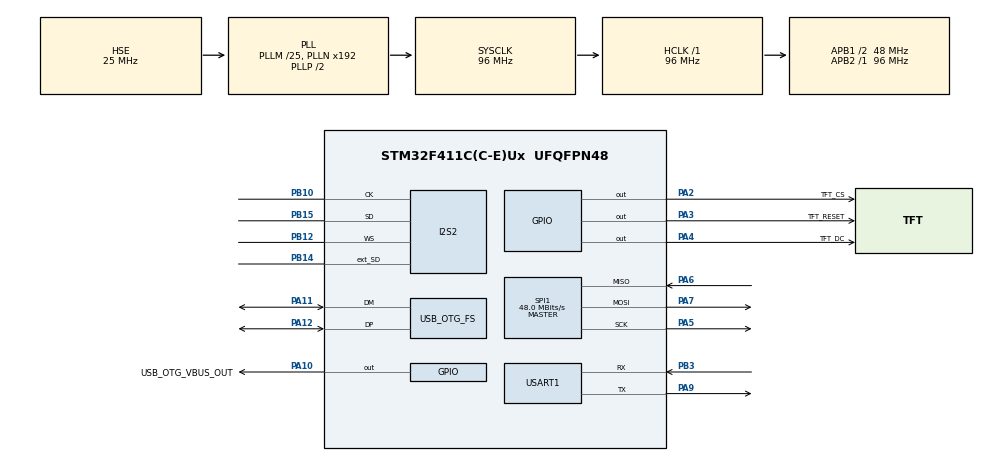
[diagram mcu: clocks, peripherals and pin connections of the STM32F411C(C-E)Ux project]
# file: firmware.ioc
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Dma.I2S2_EXT_TX.4.Direction=DMA_MEMORY_TO_PERIPH
Dma.I2S2_EXT_TX.4.FIFOMode=DMA_FIFOMODE_DISABLE
Dma.I2S2_EXT_TX.4.Instance=DMA1_Stream4
Dma.I2S2_EXT_TX.4.MemDataAlignment=DMA_MDATAALIGN_HALFWORD
Dma.I2S2_EXT_TX.4.MemInc=DMA_MINC_ENABLE
Dma.I2S2_EXT_TX.4.Mode=DMA_CIRCULAR
Dma.I2S2_EXT_TX.4.PeriphDataAlignment=DMA_PDATAALIGN_HALFWORD
Dma.I2S2_EXT_TX.4.PeriphInc=DMA_PINC_DISABLE
Dma.I2S2_EXT_TX.4.Priority=DMA_PRIORITY_VERY_HIGH
Dma.Request0=SPI1_TX
Dma.Request1=USART1_TX
Dma.Request2=USART1_RX
Dma.Request3=SPI2_RX
Dma.Request4=I2S2_EXT_TX
Dma.SPI1_TX.0.Direction=DMA_MEMORY_TO_PERIPH
Dma.SPI1_TX.0.FIFOMode=DMA_FIFOMODE_DISABLE
Dma.SPI1_TX.0.Instance=DMA2_Stream2
Dma.SPI1_TX.0.MemDataAlignment=DMA_MDATAALIGN_BYTE
Dma.SPI1_TX.0.MemInc=DMA_MINC_ENABLE
Dma.SPI1_TX.0.Mode=DMA_NORMAL
Dma.SPI1_TX.0.PeriphDataAlignment=DMA_PDATAALIGN_BYTE
Dma.SPI1_TX.0.PeriphInc=DMA_PINC_DISABLE
Dma.SPI1_TX.0.Priority=DMA_PRIORITY_LOW
Dma.SPI2_RX.3.Direction=DMA_PERIPH_TO_MEMORY
Dma.SPI2_RX.3.FIFOMode=DMA_FIFOMODE_DISABLE
Dma.SPI2_RX.3.Instance=DMA1_Stream3
Dma.SPI2_RX.3.MemDataAlignment=DMA_MDATAALIGN_HALFWORD
Dma.SPI2_RX.3.MemInc=DMA_MINC_ENABLE
Dma.SPI2_RX.3.Mode=DMA_CIRCULAR
Dma.SPI2_RX.3.PeriphDataAlignment=DMA_PDATAALIGN_HALFWORD
Dma.SPI2_RX.3.PeriphInc=DMA_PINC_DISABLE
Dma.SPI2_RX.3.Priority=DMA_PRIORITY_VERY_HIGH
Dma.USART1_RX.2.Direction=DMA_PERIPH_TO_MEMORY
Dma.USART1_RX.2.FIFOMode=DMA_FIFOMODE_DISABLE
Dma.USART1_RX.2.Instance=DMA2_Stream5
Dma.USART1_RX.2.MemDataAlignment=DMA_MDATAALIGN_BYTE
Dma.USART1_RX.2.MemInc=DMA_MINC_ENABLE
Dma.USART1_RX.2.Mode=DMA_NORMAL
Dma.USART1_RX.2.PeriphDataAlignment=DMA_PDATAALIGN_BYTE
Dma.USART1_RX.2.PeriphInc=DMA_PINC_DISABLE
Dma.USART1_RX.2.Priority=DMA_PRIORITY_LOW
Dma.USART1_TX.1.Direction=DMA_MEMORY_TO_PERIPH
Dma.USART1_TX.1.FIFOMode=DMA_FIFOMODE_DISABLE
Dma.USART1_TX.1.Instance=DMA2_Stream7
Dma.USART1_TX.1.MemDataAlignment=DMA_MDATAALIGN_BYTE
Dma.USART1_TX.1.MemInc=DMA_MINC_ENABLE
Dma.USART1_TX.1.Mode=DMA_NORMAL
Dma.USART1_TX.1.PeriphDataAlignment=DMA_PDATAALIGN_BYTE
Dma.USART1_TX.1.PeriphInc=DMA_PINC_DISABLE
Dma.USART1_TX.1.Priority=DMA_PRIORITY_LOW
FREERTOS.Tasks01=defaultTask,24,128,StartDefaultTask,Default,NULL,Dynamic,NULL,NULL
I2S2.AudioFreq=AudioFreqCustomValue
I2S2.AudioFreqCustom=44100
I2S2.ErrorAudioFreq=0.23 %
I2S2.FullDuplexMode=I2S_FULLDUPLEXMODE_ENABLE
I2S2.Instance=SPI$Index
I2S2.Mode=I2S_MODE_MASTER_RX
I2S2.RealAudioFreq=44.102 KHz
I2S2.VirtualMode=I2S_MODE_MASTER
Mcu.Family=STM32F4
Mcu.Name=STM32F411C(C-E)Ux
Mcu.Package=UFQFPN48
NVIC.DMA1_Stream3_IRQn=true\:5\:0\:false\:false\:true\:true\:false\:true
NVIC.DMA1_Stream4_IRQn=true\:5\:0\:false\:false\:true\:true\:false\:true
NVIC.DMA2_Stream2_IRQn=true\:5\:0\:false\:false\:true\:true\:false\:true
NVIC.DMA2_Stream5_IRQn=true\:5\:0\:false\:false\:true\:true\:false\:true
NVIC.DMA2_Stream7_IRQn=true\:5\:0\:false\:false\:true\:true\:false\:true
NVIC.OTG_FS_IRQn=true\:5\:0\:false\:false\:true\:true\:true\:true
NVIC.PriorityGroup=NVIC_PRIORITYGROUP_4
NVIC.SPI1_IRQn=true\:5\:0\:false\:false\:true\:true\:true\:true
NVIC.SPI2_IRQn=true\:5\:0\:false\:false\:true\:true\:true\:true
NVIC.TIM5_IRQn=true\:15\:0\:false\:false\:true\:false\:false\:true
NVIC.TimeBase=TIM5_IRQn
NVIC.TimeBaseIP=TIM5
NVIC.USART1_IRQn=true\:5\:0\:false\:false\:true\:true\:true\:true
PA10.GPIO_Label=USB_OTG_VBUS_OUT
PA10.Signal=GPIO_Output
PA11.Mode=Host_Only
PA11.Signal=USB_OTG_FS_DM
PA12.Mode=Host_Only
PA12.Signal=USB_OTG_FS_DP
PA13.Mode=Serial_Wire
PA13.Signal=SYS_JTMS-SWDIO
PA14.Mode=Serial_Wire
PA14.Signal=SYS_JTCK-SWCLK
PA2.GPIO_Label=TFT_CS
PA2.GPIO_Speed=GPIO_SPEED_FREQ_HIGH
PA2.Signal=GPIO_Output
PA3.GPIO_Label=TFT_RESET
PA3.Signal=GPIO_Output
PA4.GPIO_Label=TFT_DC
PA4.GPIO_Speed=GPIO_SPEED_FREQ_HIGH
PA4.PinState=GPIO_PIN_RESET
PA4.Signal=GPIO_Output
PA5.Mode=Full_Duplex_Master
PA5.Signal=SPI1_SCK
PA6.Mode=Full_Duplex_Master
PA6.Signal=SPI1_MISO
PA7.Mode=Full_Duplex_Master
PA7.Signal=SPI1_MOSI
PA9.Mode=Asynchronous
PA9.Signal=USART1_TX
PB10.Mode=Full_Duplex_Master
PB10.Signal=I2S2_CK
PB12.Mode=Full_Duplex_Master
PB12.Signal=I2S2_WS
PB14.Mode=Full_Duplex_Master
PB14.Signal=I2S2_ext_SD
PB15.Mode=Full_Duplex_Master
PB15.Signal=I2S2_SD
PB3.Mode=Asynchronous
PB3.Signal=USART1_RX
PC14-OSC32_IN.Mode=LSE-External-Oscillator
PC14-OSC32_IN.Signal=RCC_OSC32_IN
PC15-OSC32_OUT.Mode=LSE-External-Oscillator
PC15-OSC32_OUT.Signal=RCC_OSC32_OUT
PH0\ -\ OSC_IN.Mode=HSE-External-Oscillator
PH0\ -\ OSC_IN.Signal=RCC_OSC_IN
PH1\ -\ OSC_OUT.Mode=HSE-External-Oscillator
PH1\ -\ OSC_OUT.Signal=RCC_OSC_OUT
ProjectManager.HeapSize=0x200
ProjectManager.StackSize=0x800
ProjectManager.TargetToolchain=Makefile
RCC.48MHZClocksFreq_Value=48000000
RCC.AHBFreq_Value=96000000
RCC.APB1CLKDivider=RCC_HCLK_DIV2
RCC.APB1Freq_Value=48000000
RCC.APB1TimFreq_Value=96000000
RCC.APB2Freq_Value=96000000
RCC.APB2TimFreq_Value=96000000
RCC.CortexFreq_Value=96000000
RCC.HCLKFreq_Value=96000000
RCC.HSE_VALUE=25000000
RCC.HSI_VALUE=16000000
RCC.PLLI2SM=12
RCC.PLLI2SN=63
RCC.PLLI2SR=3
RCC.PLLM=25
RCC.SYSCLKFreq_VALUE=96000000
RCC.SYSCLKSource=RCC_SYSCLKSOURCE_PLLCLK
RCC.VCOOutputFreq_Value=192000000
SPI1.BaudRatePrescaler=SPI_BAUDRATEPRESCALER_2
SPI1.CalculateBaudRate=48.0 MBits/s
SPI1.Direction=SPI_DIRECTION_2LINES
SPI1.Mode=SPI_MODE_MASTER
SPI1.VirtualType=VM_MASTER
USART1.VirtualMode=VM_ASYNC
USB_HOST.BSP.number=1
USB_HOST.USBH_DEBUG_LEVEL=3
USB_HOST.USBH_HandleTypeDef=hUsbHostFS
USB_HOST.USBH_PROCESS_STACK_SIZE=2*1024
USB_HOST.VirtualModeFS=All_Classes
USB_HOST0.BSP.STBoard=false
USB_HOST0.BSP.api=Unknown
USB_HOST0.BSP.i2caddr=0
USB_HOST0.BSP.instance=PA10
USB_HOST0.BSP.ip=GPIO
USB_HOST0.BSP.mode=Output
USB_HOST0.BSP.name=Drive_VBUS_FS
USB_HOST0.BSP.solution=PA10
USB_OTG_FS.VirtualMode=Host_Only
USB_OTG_FS.phy_itface=HCD_PHY_EMBEDDED
VP_FREERTOS_VS_CMSIS_V2.Mode=CMSIS_V2
VP_SYS_VS_tim5.Mode=TIM5
VP_USB_HOST_VS_USB_HOST_ALL_CLASS_FS.Mode=ALL_Classes_FS
board=custom

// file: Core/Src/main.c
/* USER CODE BEGIN Header */
/**
 ******************************************************************************
 * @file           : main.c
 * @brief          : Main program body
 ******************************************************************************
 * @attention
 *
 * <h2><center>&copy; Copyright (c) 2023 STMicroelectronics.
 * All rights reserved.</center></h2>
 *
 * This software component is licensed by ST under Ultimate Liberty license
 * SLA0044, the "License"; You may not use this file except in compliance with
 * the License. You may obtain a copy of the License at:
 *                             www.st.com/SLA0044
 *
 ******************************************************************************
 */
/* USER CODE END Header */
#include "main.h"
#include "cmsis_os.h"
#include "usb_host.h"
#include "usb_host.h"

/* USER CODE BEGIN Includes */
#include "platform.h"
#include "SEGGER_SYSVIEW.h"
/* USER CODE END Includes */

I2S_HandleTypeDef hi2s2;
DMA_HandleTypeDef hdma_spi2_rx;
DMA_HandleTypeDef hdma_i2s2_ext_tx;

SPI_HandleTypeDef hspi1;
DMA_HandleTypeDef hdma_spi1_tx;

UART_HandleTypeDef huart1;
DMA_HandleTypeDef hdma_usart1_tx;
DMA_HandleTypeDef hdma_usart1_rx;

/* Definitions for defaultTask */
osThreadId_t defaultTaskHandle;
const osThreadAttr_t defaultTask_attributes = {
  .name = "defaultTask",
  .stack_size = 128 * 4,
  .priority = (osPriority_t) osPriorityNormal,
};

void SystemClock_Config(void);
static void MX_GPIO_Init(void);
static void MX_DMA_Init(void);
static void MX_SPI1_Init(void);
static void MX_USART1_UART_Init(void);
static void MX_I2S2_Init(void);
void StartDefaultTask(void *argument);

/* USER CODE BEGIN 0 */
static volatile int uxTopUsedPriority;

/* USER CODE END 0 */

int main(void)
{
  /* USER CODE BEGIN 1 */
  uxTopUsedPriority = configMAX_PRIORITIES - 1;
  SEGGER_SYSVIEW_Conf();
  /* USER CODE END 1 */

  /* MCU Configuration--------------------------------------------------------*/

  /* Reset of all peripherals, Initializes the Flash interface and the Systick. */
  HAL_Init();

  /* Configure the system clock */
  SystemClock_Config();

  /* Initialize all configured peripherals */
  MX_GPIO_Init();
  MX_DMA_Init();
  MX_SPI1_Init();
  MX_USART1_UART_Init();
  MX_I2S2_Init();

  /* Init scheduler */
  osKernelInitialize();

  /* Create the thread(s) */
  /* creation of defaultTask */
  defaultTaskHandle = osThreadNew(StartDefaultTask, NULL, &defaultTask_attributes);

  /* Start scheduler */
  osKernelStart();

  /* We should never get here as control is now taken by the scheduler */
  /* Infinite loop */
    while (1) {

    }
}

void SystemClock_Config(void)
{
  RCC_OscInitTypeDef RCC_OscInitStruct = {0};
  RCC_ClkInitTypeDef RCC_ClkInitStruct = {0};

  /** Configure the main internal regulator output voltage
  */
  __HAL_RCC_PWR_CLK_ENABLE();
  __HAL_PWR_VOLTAGESCALING_CONFIG(PWR_REGULATOR_VOLTAGE_SCALE1);
  /** Initializes the RCC Oscillators according to the specified parameters
  * in the RCC_OscInitTypeDef structure.
  */
  RCC_OscInitStruct.OscillatorType = RCC_OSCILLATORTYPE_HSE;
  RCC_OscInitStruct.HSEState = RCC_HSE_ON;
  RCC_OscInitStruct.PLL.PLLState = RCC_PLL_ON;
  RCC_OscInitStruct.PLL.PLLSource = RCC_PLLSOURCE_HSE;
  RCC_OscInitStruct.PLL.PLLM = 25;
  RCC_OscInitStruct.PLL.PLLN = 192;
  RCC_OscInitStruct.PLL.PLLP = RCC_PLLP_DIV2;
  RCC_OscInitStruct.PLL.PLLQ = 4;
  if (HAL_RCC_OscConfig(&RCC_OscInitStruct) != HAL_OK)
  {
    Error_Handler();
  }
  /** Initializes the CPU, AHB and APB buses clocks
  */
  RCC_ClkInitStruct.ClockType = RCC_CLOCKTYPE_HCLK|RCC_CLOCKTYPE_SYSCLK
                              |RCC_CLOCKTYPE_PCLK1|RCC_CLOCKTYPE_PCLK2;
  RCC_ClkInitStruct.SYSCLKSource = RCC_SYSCLKSOURCE_PLLCLK;
  RCC_ClkInitStruct.AHBCLKDivider = RCC_SYSCLK_DIV1;
  RCC_ClkInitStruct.APB1CLKDivider = RCC_HCLK_DIV2;
  RCC_ClkInitStruct.APB2CLKDivider = RCC_HCLK_DIV1;

  if (HAL_RCC_ClockConfig(&RCC_ClkInitStruct, FLASH_LATENCY_3) != HAL_OK)
  {
    Error_Handler();
  }
}

static void MX_I2S2_Init(void)
{

  hi2s2.Instance = SPI2;
  hi2s2.Init.Mode = I2S_MODE_MASTER_RX;
  hi2s2.Init.Standard = I2S_STANDARD_PHILIPS;
  hi2s2.Init.DataFormat = I2S_DATAFORMAT_16B;
  hi2s2.Init.MCLKOutput = I2S_MCLKOUTPUT_DISABLE;
  hi2s2.Init.AudioFreq = 44100;
  hi2s2.Init.CPOL = I2S_CPOL_LOW;
  hi2s2.Init.ClockSource = I2S_CLOCK_PLL;
  hi2s2.Init.FullDuplexMode = I2S_FULLDUPLEXMODE_ENABLE;
  if (HAL_I2S_Init(&hi2s2) != HAL_OK)
  {
    Error_Handler();
  }

}

static void MX_SPI1_Init(void)
{

  /* SPI1 parameter configuration*/
  hspi1.Instance = SPI1;
  hspi1.Init.Mode = SPI_MODE_MASTER;
  hspi1.Init.Direction = SPI_DIRECTION_2LINES;
  hspi1.Init.DataSize = SPI_DATASIZE_8BIT;
  hspi1.Init.CLKPolarity = SPI_POLARITY_LOW;
  hspi1.Init.CLKPhase = SPI_PHASE_1EDGE;
  hspi1.Init.NSS = SPI_NSS_SOFT;
  hspi1.Init.BaudRatePrescaler = SPI_BAUDRATEPRESCALER_2;
  hspi1.Init.FirstBit = SPI_FIRSTBIT_MSB;
  hspi1.Init.TIMode = SPI_TIMODE_DISABLE;
  hspi1.Init.CRCCalculation = SPI_CRCCALCULATION_DISABLE;
  hspi1.Init.CRCPolynomial = 10;
  if (HAL_SPI_Init(&hspi1) != HAL_OK)
  {
    Error_Handler();
  }

}

static void MX_USART1_UART_Init(void)
{

  huart1.Instance = USART1;
  huart1.Init.BaudRate = 921600;
  huart1.Init.WordLength = UART_WORDLENGTH_8B;
  huart1.Init.StopBits = UART_STOPBITS_1;
  huart1.Init.Parity = UART_PARITY_NONE;
  huart1.Init.Mode = UART_MODE_TX_RX;
  huart1.Init.HwFlowCtl = UART_HWCONTROL_NONE;
  huart1.Init.OverSampling = UART_OVERSAMPLING_16;
  if (HAL_UART_Init(&huart1) != HAL_OK)
  {
    Error_Handler();
  }

}

static void MX_DMA_Init(void)
{

  /* DMA controller clock enable */
  __HAL_RCC_DMA2_CLK_ENABLE();
  __HAL_RCC_DMA1_CLK_ENABLE();

  /* DMA interrupt init */
  /* DMA1_Stream3_IRQn interrupt configuration */
  HAL_NVIC_SetPriority(DMA1_Stream3_IRQn, 5, 0);
  HAL_NVIC_EnableIRQ(DMA1_Stream3_IRQn);
  /* DMA1_Stream4_IRQn interrupt configuration */
  HAL_NVIC_SetPriority(DMA1_Stream4_IRQn, 5, 0);
  HAL_NVIC_EnableIRQ(DMA1_Stream4_IRQn);
  /* DMA2_Stream2_IRQn interrupt configuration */
  HAL_NVIC_SetPriority(DMA2_Stream2_IRQn, 5, 0);
  HAL_NVIC_EnableIRQ(DMA2_Stream2_IRQn);
  /* DMA2_Stream5_IRQn interrupt configuration */
  HAL_NVIC_SetPriority(DMA2_Stream5_IRQn, 5, 0);
  HAL_NVIC_EnableIRQ(DMA2_Stream5_IRQn);
  /* DMA2_Stream7_IRQn interrupt configuration */
  HAL_NVIC_SetPriority(DMA2_Stream7_IRQn, 5, 0);
  HAL_NVIC_EnableIRQ(DMA2_Stream7_IRQn);

}

static void MX_GPIO_Init(void)
{
  GPIO_InitTypeDef GPIO_InitStruct = {0};

  /* GPIO Ports Clock Enable */
  __HAL_RCC_GPIOC_CLK_ENABLE();
  __HAL_RCC_GPIOH_CLK_ENABLE();
  __HAL_RCC_GPIOA_CLK_ENABLE();
  __HAL_RCC_GPIOB_CLK_ENABLE();

  /*Configure GPIO pin Output Level */
  HAL_GPIO_WritePin(GPIOA, TFT_CS_Pin|TFT_RESET_Pin|TFT_DC_Pin|USB_OTG_VBUS_OUT_Pin, GPIO_PIN_RESET);

  /*Configure GPIO pins : TFT_CS_Pin TFT_DC_Pin */
  GPIO_InitStruct.Pin = TFT_CS_Pin|TFT_DC_Pin;
  GPIO_InitStruct.Mode = GPIO_MODE_OUTPUT_PP;
  GPIO_InitStruct.Pull = GPIO_NOPULL;
  GPIO_InitStruct.Speed = GPIO_SPEED_FREQ_HIGH;
  HAL_GPIO_Init(GPIOA, &GPIO_InitStruct);

  /*Configure GPIO pins : TFT_RESET_Pin USB_OTG_VBUS_OUT_Pin */
  GPIO_InitStruct.Pin = TFT_RESET_Pin|USB_OTG_VBUS_OUT_Pin;
  GPIO_InitStruct.Mode = GPIO_MODE_OUTPUT_PP;
  GPIO_InitStruct.Pull = GPIO_NOPULL;
  GPIO_InitStruct.Speed = GPIO_SPEED_FREQ_LOW;
  HAL_GPIO_Init(GPIOA, &GPIO_InitStruct);

}

/* USER CODE BEGIN 4 */
uint16_t audio_out_buffer[256];
/* USER CODE END 4 */

void StartDefaultTask(void *argument)
{
  SEGGER_SYSVIEW_Start();
  /* init code for USB_HOST */
  MX_USB_HOST_Init();
  /* USER CODE BEGIN 5 */
  platform_app();
//   HAL_I2S_Transmit_DMA(&hi2s2, audio_out_buffer, 256);
  osThreadTerminate(defaultTaskHandle);
  /* USER CODE END 5 */
}

void HAL_TIM_PeriodElapsedCallback(TIM_HandleTypeDef *htim)
{
  if (htim->Instance == TIM5) {
    HAL_IncTick();
  }
}

void Error_Handler(void)
{
    __disable_irq();
    while (1) {
    }
}

#ifdef  USE_FULL_ASSERT
/**
  * @brief  Reports the name of the source file and the source line number
  *         where the assert_param error has occurred.
  * @param  file: pointer to the source file name
  * @param  line: assert_param error line source number
  * @retval None
  */
void assert_failed(uint8_t *file, uint32_t line)
{
  /* USER CODE BEGIN 6 */
    /* User can add his own implementation to report the file name and line
       number,
       ex: printf("Wrong parameters value: file %s on line %d\r\n", file, line) */
  /* USER CODE END 6 */
}
#endif /* USE_FULL_ASSERT */

/************************ (C) COPYRIGHT STMicroelectronics *****END OF FILE****/
